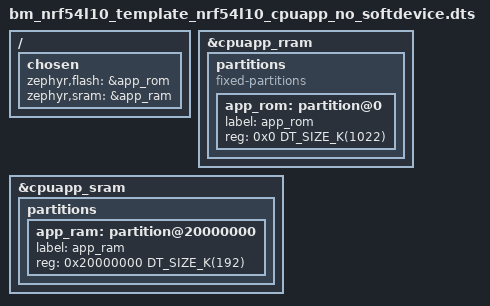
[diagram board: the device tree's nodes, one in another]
/*
 * Copyright (c) 2025 Nordic Semiconductor ASA
 *
 * SPDX-License-Identifier: LicenseRef-Nordic-5-Clause
 */

 /* No changes needed to this file */

/dts-v1/;

#include <nordic/nrf54l10_cpuapp.dtsi>
#include "cpuapp_common.dtsi"

/ {
	chosen {
		/delete-property/ zephyr,code-partition;
		zephyr,flash = &app_rom;
		zephyr,sram = &app_ram;
	};
};

&cpuapp_rram {
	status = "okay";

	partitions {
		compatible = "fixed-partitions";
		#address-cells = <1>;
		#size-cells = <1>;

		app_rom: partition@0 {
			label = "app_rom";
			reg = <0x0 DT_SIZE_K(1022)>;
		};
	};
};

&cpuapp_sram {
	status = "okay";

	partitions {
		#address-cells = <1>;
		#size-cells = <1>;

		app_ram: partition@20000000 {
			label = "app_ram";
			reg = <0x20000000 DT_SIZE_K(192)>;
		};
	};
};
